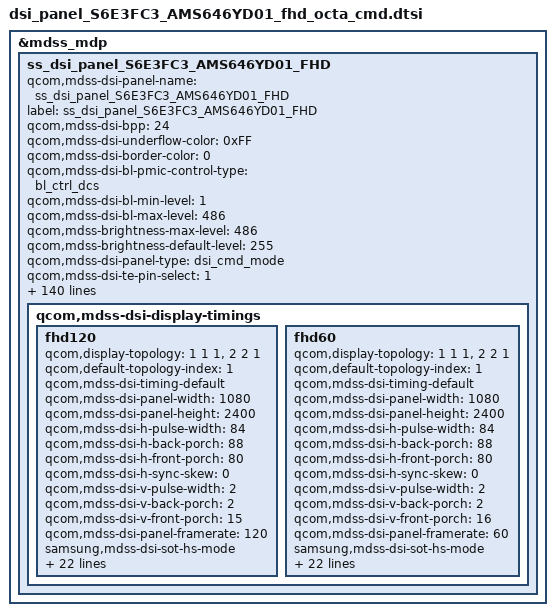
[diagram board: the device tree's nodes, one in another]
/* Copyright (c) 2012, Samsung Electronics Corporation. All rights reserved.
 *
 * This program is free software; you can redistribute it and/or modify
 * it under the terms of the GNU General Public License version 2 and
 * only version 2 as published by the Free Software Foundation.
 *
 * This program is distributed in the hope that it will be useful,
 * but WITHOUT ANY WARRANTY; without even the implied warranty of
 * MERCHANTABILITY or FITNESS FOR A PARTICULAR PURPOSE.  See the
 * GNU General Public License for more details.
 */

&mdss_mdp {
	ss_dsi_panel_S6E3FC3_AMS646YD01_FHD: ss_dsi_panel_S6E3FC3_AMS646YD01_FHD {
		qcom,mdss-dsi-panel-name = "ss_dsi_panel_S6E3FC3_AMS646YD01_FHD";
		label = "ss_dsi_panel_S6E3FC3_AMS646YD01_FHD";

		qcom,mdss-dsi-bpp = <24>;

		qcom,mdss-dsi-underflow-color = <0xFF>;
		qcom,mdss-dsi-border-color = <0>;

		qcom,mdss-dsi-bl-pmic-control-type = "bl_ctrl_dcs";

		qcom,mdss-dsi-bl-min-level = <1>;
		qcom,mdss-dsi-bl-max-level = <486>;
		qcom,mdss-brightness-max-level = <486>;
		qcom,mdss-brightness-default-level = <255>;

		qcom,mdss-dsi-panel-type = "dsi_cmd_mode";

		qcom,mdss-dsi-te-pin-select = <1>;

		qcom,mdss-dsi-te-dcs-command = <1>;
		qcom,mdss-dsi-wr-mem-start = <0x2C>;
		qcom,mdss-dsi-wr-mem-continue = <0x3C>;

		qcom,mdss-dsi-pixel-packing = "loose";

		qcom,mdss-dsi-virtual-channel-id = <0>;
		qcom,mdss-dsi-color-order = "rgb_swap_rgb";
		qcom,mdss-dsi-lane-0-state;
		qcom,mdss-dsi-lane-1-state;
		qcom,mdss-dsi-lane-2-state;
		qcom,mdss-dsi-lane-3-state;
		qcom,mdss-dsi-lane-map = "lane_map_0123";

		qcom,mdss-dsi-t-clk-pre = <0x3E>;
		qcom,mdss-dsi-t-clk-post = <0x10>;

		qcom,mdss-dsi-stream = <0>;
		qcom,mdss-dsi-mdp-trigger = "none";
		qcom,mdss-dsi-dma-trigger = "trigger_sw";

		qcom,mdss-pan-physical-width-dimension = <67>; /* 67.284 round-off */
		qcom,mdss-pan-physical-height-dimension = <150>; /* 149.520 round-off */

		qcom,mdss-dsi-reset-sequence = <0 10>, <1 10>;

		qcom,mdss-dsi-lp11-init;
		/*qcom,mdss-dsi-init-delay-us = <1000>;*/

		qcom,mdss-dsi-rx-eot-ignore;
		qcom,mdss-dsi-tx-eot-append;

		/* HDR Setting */
		/*qcom,mdss-dsi-panel-hdr-enabled;*/
		/*qcom,mdss-dsi-panel-hdr-color-primaries = <15635 16450 34000 16000 13250 34500 7500 3000>;*/
		/*qcom,mdss-dsi-panel-peak-brightness = <5400000>;*/
		/*qcom,mdss-dsi-panel-average-brightness = <2000000>;*/
		/*qcom,mdss-dsi-panel-blackness-level = <2000>;*/

		qcom,ulps-enabled;

		/* qcom,suspend-ulps-enabled; */
		qcom,esd-check-enabled;
		qcom,mdss-dsi-panel-status-check-mode ="irq_check";
		qcom,mdss-dsi-panel-status-irq-trigger1 = "falling";
		/*qcom,mdss-dsi-panel-status-read-length;*/
		/*qcom,mdss-dsi-panel-status-value;*/
		/*qcom,mdss-dsi-panel-status-irq-trigger1 = "rising";*/

		/* *************************************************************
		 * Below  parameters are samsung dependent thigs
		 * *************************************************************
		 */
		samsung,panel-vendor = "SDC";
		samsung,disp-model = "AMS646YD01";
		samsung,panel-lpm-enable;
		samsung,support_gamma_mode2;
		samsung,skip_read_on_pre;
		samsung,elvss_interpolation_temperature = <(-16)>;
		samsung,support_lpm;
		samsung,rsc_4_frame_idle;
		samsung,support_factory_panel_swap;
		samsung,support-optical-fingerprint;

		samsung,support_vrr_based_bl; /* VRR Variable Refresh Rate */

		//samsung,esd-irq-trigger1 = "falling"; /* FG_ERR */

		/* *************************************************************
		 *  SELF DISPLAY
		 * *************************************************************
		 */
		//ss,self_display = <&self_display_FC3_dtsi>;

		/* *************************************************************
		 *  Tx
		 * *************************************************************
		 */
		samsung,level0_key_enable_tx_cmds_revA	= [29 01 00 00 00 00 03 9F A5 A5]; /* PASSWD0 */
		samsung,level0_key_disable_tx_cmds_revA	= [29 01 00 00 00 00 03 9F 5A 5A]; /* PASSWD0 */
		samsung,level1_key_enable_tx_cmds_revA	= [29 01 00 00 00 00 03 F0 5A 5A]; /* PASSWD1 */
		samsung,level1_key_disable_tx_cmds_revA	= [29 01 00 00 00 00 03 F0 A5 A5]; /* PASSWD1 */
		samsung,level2_key_enable_tx_cmds_revA	= [29 01 00 00 00 00 03 FC 5A 5A];
		samsung,level2_key_disable_tx_cmds_revA	= [29 01 00 00 00 00 03 FC A5 A5];

		/* BRIGHTNESS_MAX_PACKET = 50 */
		samsung,brightness_tx_cmds_revA = [
			39 01 00 00 00 00 01 00
			39 01 00 00 00 00 01 00
			39 01 00 00 00 00 01 00
			39 01 00 00 00 00 01 00
			39 01 00 00 00 00 01 00
			39 01 00 00 00 00 01 00
			39 01 00 00 00 00 01 00
			39 01 00 00 00 00 01 00
			39 01 00 00 00 00 01 00
			39 01 00 00 00 00 01 00
			39 01 00 00 00 00 01 00
			39 01 00 00 00 00 01 00
			39 01 00 00 00 00 01 00
			39 01 00 00 00 00 01 00
			39 01 00 00 00 00 01 00
			39 01 00 00 00 00 01 00
			39 01 00 00 00 00 01 00
			39 01 00 00 00 00 01 00
			39 01 00 00 00 00 01 00
			39 01 00 00 00 00 01 00
			39 01 00 00 00 00 01 00
			39 01 00 00 00 00 01 00
			39 01 00 00 00 00 01 00
			39 01 00 00 00 00 01 00
			39 01 00 00 00 00 01 00
			39 01 00 00 00 00 01 00
			39 01 00 00 00 00 01 00
			39 01 00 00 00 00 01 00
			39 01 00 00 00 00 01 00
			39 01 00 00 00 00 01 00
			39 01 00 00 00 00 01 00
			39 01 00 00 00 00 01 00
			39 01 00 00 00 00 01 00
			39 01 00 00 00 00 01 00
			39 01 00 00 00 00 01 00
			39 01 00 00 00 00 01 00
			39 01 00 00 00 00 01 00
			39 01 00 00 00 00 01 00
			39 01 00 00 00 00 01 00
			39 01 00 00 00 00 01 00
			39 01 00 00 00 00 01 00
			39 01 00 00 00 00 01 00
			39 01 00 00 00 00 01 00
			39 01 00 00 00 00 01 00
			39 01 00 00 00 00 01 00
			39 01 00 00 00 00 01 00
			39 01 00 00 00 00 01 00
			39 01 00 00 00 00 01 00
			39 01 00 00 00 00 01 00
			39 01 00 00 00 00 01 00
		];

		samsung,display_on_tx_cmds_revA = [
			/* DSC PPS cmd unlock & lock LEVEL0 KEY */
			29 00 00 00 00 00 03 9F A5 A5
			05 00 00 00 00 00 02 29 00
			29 01 00 00 00 00 03 9F 5A 5A
		];

		samsung,display_off_tx_cmds_revA = [05 01 00 00 00 00 02 28 00];

		samsung,reg_read_pos_tx_cmds_revA = [29 00 00 00 00 00 04 B0 00 00 00];

		samsung,mtp_write_sysfs_tx_cmds_revA = [
			29 00 00 00 00 00 3D 00
			00 00 00 00 00 00 00 00 00 00
			00 00 00 00 00 00 00 00 00 00
			00 00 00 00 00 00 00 00 00 00
			00 00 00 00 00 00 00 00 00 00
			00 00 00 00 00 00 00 00 00 00
			00 00 00 00 00 00 00 00 00 00
		];

		samsung,smooth_dimming_off_tx_cmds_revA = [
			29 00 00 00 00 00 03 F0 5A 5A
			29 01 00 00 21 00 02 53 20
			29 01 00 00 00 00 03 F0 A5 A5
		];

		samsung,gamma_mode2_normal_tx_cmds_revI=[
			29 00 00 00 00 00 04 B0 00 91 63
			29 00 00 00 00 00 02 63 60	/* hbm setting 1 */

			29 00 00 00 00 00 04 B0 02 03 63
			29 00 00 00 00 00 03 63 f1 07	/* hbm setting 2 */

			29 00 00 00 00 00 02 53 20	/* dimming speed setting */
			29 00 00 00 00 00 03 51 03 FF	/* WRDISBV */
			29 00 00 00 00 00 02 B5 14	/* temperature */

			29 00 00 00 00 00 04 B0 02 03 63
			29 00 00 00 00 00 03 63 f0 00	/* hbm setting 2 */

			29 00 00 00 00 00 04 B0 00 76 63
			29 00 00 00 00 00 04 63 00 00 00 /* AOR */
		];

		samsung,gamma_mode2_normal_tx_cmds_revG=[
			29 00 00 00 00 00 03 91 02 01	 /* normal brightness */
			29 00 00 00 00 00 02 53 20	/* dimming speed setting */
			29 00 00 00 00 00 03 51 03 FF	/* WRDISBV */
			29 00 00 00 00 00 02 B5 14	/* temperature */
			29 00 00 00 00 00 04 B0 00 76 63
			29 00 00 00 00 00 04 63 00 00 00 /* AOR */
		];

		samsung,gamma_mode2_normal_tx_cmds_revA=[
			29 00 00 00 00 00 04 B0 00 91 63
			29 00 00 00 00 00 02 63 60	/* hbm setting 1 */

			29 00 00 00 00 00 04 B0 02 03 63
			29 00 00 00 00 00 03 63 f1 07	/* hbm setting 2 */

			29 00 00 00 00 00 02 53 20	/* dimming speed setting */
			29 00 00 00 00 00 03 51 03 FF	/* WRDISBV */
			29 00 00 00 00 00 02 B5 14	/* temperature */

			29 00 00 00 00 00 04 B0 02 03 63
			29 00 00 00 00 00 03 63 f0 00	/* hbm setting 2 */
		];

		samsung,gamma_mode2_hbm_tx_cmds_revI=[
			29 00 00 00 00 00 04 B0 00 91 63
			29 00 00 00 00 00 02 63 20	/* hbm setting 1 */

			29 00 00 00 00 00 04 B0 02 03 63
			29 00 00 00 00 00 03 63 f1 00	/* hbm setting 2 */

			29 00 00 00 00 00 02 53 E0	/* dimming speed setting */
			29 00 00 00 00 00 03 51 03 FF	/* WRDISBV */
			29 00 00 00 00 00 02 B5 14	/* temperature */

			29 00 00 00 00 00 04 B0 02 03 63
			29 00 00 00 00 00 03 63 f0 07	/* hbm setting 2 */

			29 00 00 00 00 00 04 B0 00 76 63
			29 00 00 00 00 00 04 63 00 00 00 /* AOR */
		];

		samsung,gamma_mode2_hbm_tx_cmds_revG=[
			29 00 00 00 00 00 03 91 02 00	 /* hbm brightness */
			29 00 00 00 00 00 02 53 E0	/* dimming speed setting */
			29 00 00 00 00 00 03 51 03 FF	/* WRDISBV */
			29 00 00 00 00 00 02 B5 14	/* temperature */
			29 00 00 00 00 00 04 B0 00 76 63
			29 00 00 00 00 00 04 63 00 00 00 /* AOR */
		];

		samsung,gamma_mode2_hbm_tx_cmds_revA=[
			29 00 00 00 00 00 04 B0 00 91 63
			29 00 00 00 00 00 02 63 20	/* hbm setting 1 */

			29 00 00 00 00 00 04 B0 02 03 63
			29 00 00 00 00 00 03 63 f1 00	/* hbm setting 2 */

			29 00 00 00 00 00 02 53 E0	/* dimming speed setting */
			29 00 00 00 00 00 03 51 03 FF	/* WRDISBV */
			29 00 00 00 00 00 02 B5 14	/* temperature */

			29 00 00 00 00 00 04 B0 02 03 63
			29 00 00 00 00 00 03 63 f0 07	/* hbm setting 2 */
		];

		samsung,vrr_tx_cmds_revA = [
			29 00 00 00 00 00 03 60 00 00
			29 00 00 00 00 00 02 F7 0F
		];

		samsung,acl_on_tx_cmds_revA = [
			29 00 00 00 00 00 04 B0 03 B3 65
			29 00 00 00 00 00 14 65
				55 00 B0 51 66 98 15 55 55 55	/* 32 Frame Avg & ACL start step 50% */
				08 F1 C6 48 40 00 20 10 09	/* ACL Dimming : 32 frame */
			29 00 00 00 00 00 02 55 03		/* normal ACL 15% & HBM ACL 8% */
		];

		samsung,acl_off_tx_cmds_revA = [
			29 01 00 00 00 00 02 55 00		/* ACL OFF */
		];

		/* *************************************************************
		 *  Rx (Module Information READ)
		 * *************************************************************
		 */
		samsung,manufacture_id0_rx_cmds_revA	= [06 01 00 00 00 00 01 da 01 00];
		samsung,manufacture_id1_rx_cmds_revA	= [06 01 00 00 00 00 01 db 01 00];
		samsung,manufacture_id2_rx_cmds_revA	= [06 01 00 00 00 00 01 dc 01 00];

		samsung,module_info_rx_cmds_revA = [06 01 00 00 00 00 01 A1 0B 00];
		samsung,octa_id_rx_cmds_revA	= [06 01 00 00 00 00 01 A1 04 0B]; /* OCTA ID : read A1 12th ~ 15th + Cell ID */
		samsung,cell_id_rx_cmds_revA	= [06 01 00 00 00 00 01 92 10 02]; /* CELL ID : read 92 3rd~18th bytes*/
		samsung,ddi_id_rx_cmds_revA	= [06 01 00 00 00 00 01 D6 05 00];

		samsung,mtp_read_sysfs_rx_cmds_revA = [06 01 00 00 00 00 01 00 00 00];

		/* *************************************************************
		 * candela to index mappings
		 * **************************************************************
		 */
		samsung,candela_map_table_revA = < /* THIS TABLE USED FOR DIMMING */
		/* <idx> <from> <till> <gm2_wrdisbv> <cd> */
			0	0	0	2	2
			1	1	1	2	2
			2	2	2	5	3
			3	3	3	5	3
			4	4	4	8	4
			5	5	5	8	4
			6	6	6	11	6
			7	7	7	11	6
			8	8	8	14	7
			9	9	9	14	7
			10	10	10	17	8
			11	11	11	20	9
			12	12	12	24	11
			13	13	13	24	11
			14	14	14	27	12
			15	15	15	29	13
			16	16	16	31	14
			17	17	17	34	15
			18	18	18	36	16
			19	19	19	39	17
			20	20	20	41	18
			21	21	21	44	19
			22	22	22	46	20
			23	23	23	49	21
			24	24	24	52	22
			25	25	25	54	23
			26	26	26	57	24
			27	27	27	60	25
			28	28	28	63	26
			29	29	29	66	27
			30	30	30	68	28
			31	31	31	71	29
			32	32	32	74	31
			33	33	33	77	32
			34	34	34	80	33
			35	35	35	83	34
			36	36	36	86	35
			37	37	37	89	37
			38	38	38	92	38
			39	39	39	95	39
			40	40	40	98	40
			41	41	41	102	42
			42	42	42	105	43
			43	43	43	108	44
			44	44	44	111	45
			45	45	45	114	47
			46	46	46	118	48
			47	47	47	121	49
			48	48	48	124	51
			49	49	49	128	52
			50	50	50	131	53
			51	51	51	134	55
			52	52	52	138	56
			53	53	53	141	57
			54	54	54	145	59
			55	55	55	148	60
			56	56	56	151	61
			57	57	57	155	63
			58	58	58	158	64
			59	59	59	162	65
			60	60	60	165	67
			61	61	61	169	68
			62	62	62	173	70
			63	63	63	176	71
			64	64	64	180	73
			65	65	65	183	74
			66	66	66	187	75
			67	67	67	191	77
			68	68	68	194	78
			69	69	69	198	80
			70	70	70	202	81
			71	71	71	205	83
			72	72	72	209	84
			73	73	73	213	86
			74	74	74	217	87
			75	75	75	220	89
			76	76	76	224	90
			77	77	77	228	92
			78	78	78	232	93
			79	79	79	236	95
			80	80	80	240	96
			81	81	81	243	98
			82	82	82	247	99
			83	83	83	251	101
			84	84	84	255	102
			85	85	85	259	104
			86	86	86	263	106
			87	87	87	267	107
			88	88	88	271	109
			89	89	89	275	110
			90	90	90	279	112
			91	91	91	283	113
			92	92	92	287	115
			93	93	93	291	117
			94	94	94	295	118
			95	95	95	299	120
			96	96	96	303	122
			97	97	97	307	123
			98	98	98	311	125
			99	99	99	315	126
			100	100	100	319	128
			101	101	101	324	130
			102	102	102	328	131
			103	103	103	332	133
			104	104	104	336	135
			105	105	105	340	136
			106	106	106	344	138
			107	107	107	349	140
			108	108	108	353	141
			109	109	109	357	143
			110	110	110	361	145
			111	111	111	366	146
			112	112	112	370	148
			113	113	113	374	150
			114	114	114	378	151
			115	115	115	383	153
			116	116	116	387	155
			117	117	117	391	157
			118	118	118	396	158
			119	119	119	400	160
			120	120	120	404	162
			121	121	121	409	163
			122	122	122	413	165
			123	123	123	418	167
			124	124	124	422	169
			125	125	125	426	170
			126	126	126	431	172
			127	127	127	435	174
			128	128	128	440	176
			129	129	129	444	177
			130	130	130	449	179
			131	131	131	453	181
			132	132	132	457	183
			133	133	133	462	185
			134	134	134	466	186
			135	135	135	470	188
			136	136	136	475	190
			137	137	137	479	192
			138	138	138	483	194
			139	139	139	487	195
			140	140	140	492	197
			141	141	141	496	199
			142	142	142	500	201
			143	143	143	505	203
			144	144	144	509	204
			145	145	145	513	206
			146	146	146	518	208
			147	147	147	522	210
			148	148	148	527	212
			149	149	149	531	214
			150	150	150	535	215
			151	151	151	540	217
			152	152	152	544	219
			153	153	153	549	221
			154	154	154	553	223
			155	155	155	558	225
			156	156	156	562	227
			157	157	157	566	229
			158	158	158	571	230
			159	159	159	575	232
			160	160	160	580	234
			161	161	161	584	236
			162	162	162	589	238
			163	163	163	593	240
			164	164	164	598	242
			165	165	165	603	244
			166	166	166	607	246
			167	167	167	612	247
			168	168	168	616	249
			169	169	169	621	251
			170	170	170	625	253
			171	171	171	630	255
			172	172	172	635	257
			173	173	173	639	259
			174	174	174	644	261
			175	175	175	648	263
			176	176	176	653	265
			177	177	177	658	267
			178	178	178	662	269
			179	179	179	667	271
			180	180	180	672	273
			181	181	181	676	275
			182	182	182	681	276
			183	183	183	686	278
			184	184	184	690	280
			185	185	185	695	282
			186	186	186	700	284
			187	187	187	704	286
			188	188	188	709	288
			189	189	189	714	290
			190	190	190	718	292
			191	191	191	723	294
			192	192	192	728	296
			193	193	193	733	298
			194	194	194	737	300
			195	195	195	742	302
			196	196	196	747	304
			197	197	197	752	306
			198	198	198	757	308
			199	199	199	761	310
			200	200	200	766	312
			201	201	201	771	314
			202	202	202	776	316
			203	203	203	781	318
			204	204	204	786	320
			205	205	205	790	322
			206	206	206	795	324
			207	207	207	800	326
			208	208	208	805	329
			209	209	209	810	331
			210	210	210	815	333
			211	211	211	820	335
			212	212	212	824	337
			213	213	213	829	339
			214	214	214	834	341
			215	215	215	839	343
			216	216	216	844	345
			217	217	217	847	346
			218	218	218	852	348
			219	219	219	856	350
			220	220	220	860	352
			221	221	221	864	354
			222	222	222	869	355
			223	223	223	873	357
			224	224	224	878	359
			225	225	225	882	361
			226	226	226	887	363
			227	227	227	892	365
			228	228	228	897	367
			229	229	229	903	370
			230	230	230	909	372
			231	231	231	913	374
			232	232	232	918	376
			233	233	233	923	378
			234	234	234	928	380
			235	235	235	932	382
			236	236	236	936	384
			237	237	237	940	385
			238	238	238	944	387
			239	239	239	949	389
			240	240	240	954	391
			241	241	241	959	393
			242	242	242	963	395
			243	243	243	968	397
			244	244	244	973	399
			245	245	245	978	401
			246	246	246	982	403
			247	247	247	988	405
			248	248	248	993	408
			249	249	249	999	410
			250	250	250	1004	412
			251	251	251	1008	414
			252	252	252	1012	415
			253	253	253	1015	417
			254	254	254	1019	418
			255	255	255	1023	420
		>;

		samsung,hbm_candela_map_table_revI = <
		/* <idx> <from> <till> <gm2_wrdisbv> <cd>*/
			0	256	256	2	427	0
			1	257	257	4	429	0
			2	258	258	6	430	0
			3	259	259	9	432	0
			4	260	260	12	434	0
			5	261	261	14	435	0
			6	262	262	17	437	0
			7	263	263	19	439	0
			8	264	264	21	440	0
			9	265	265	24	442	0
			10	266	266	27	443	0
			11	267	267	29	445	0
			12	268	268	32	446	0
			13	269	269	34	448	0
			14	270	270	36	450	0
			15	271	271	39	451	0
			16	272	272	42	453	0
			17	273	273	44	454	0
			18	274	274	47	456	0
			19	275	275	49	458	0
			20	276	276	51	459	0
			21	277	277	54	461	0
			22	278	278	57	463	0
			23	279	279	59	464	0
			24	280	280	62	466	0
			25	281	281	64	468	0
			26	282	282	66	469	0
			27	283	283	69	471	0
			28	284	284	72	473	0
			29	285	285	74	474	0
			30	286	286	77	476	0
			31	287	287	79	478	0
			32	288	288	81	479	0
			33	289	289	84	481	0
			34	290	290	87	482	0
			35	291	291	89	484	0
			36	292	292	92	485	0
			37	293	293	94	487	0
			38	294	294	96	488	0
			39	295	295	99	490	0
			40	296	296	102	492	0
			41	297	297	104	493	0
			42	298	298	106	495	0
			43	299	299	109	497	0
			44	300	300	111	498	0
			45	301	301	114	500	0
			46	302	302	117	502	0
			47	303	303	119	503	0
			48	304	304	121	505	0
			49	305	305	124	507	0
			50	306	306	126	508	0
			51	307	307	129	510	0
			52	308	308	132	512	0
			53	309	309	134	513	0
			54	310	310	136	515	0
			55	311	311	139	516	0
			56	312	312	141	518	0
			57	313	313	144	519	0
			58	314	314	147	521	0
			59	315	315	149	523	0
			60	316	316	151	524	0
			61	317	317	154	526	0
			62	318	318	156	527	0
			63	319	319	159	529	0
			64	320	320	162	531	0
			65	321	321	164	532	0
			66	322	322	166	534	0
			67	323	323	169	536	0
			68	324	324	171	537	0
			69	325	325	174	539	0
			70	326	326	177	541	0
			71	327	327	179	542	0
			72	328	328	181	544	0
			73	329	329	184	546	0
			74	330	330	186	547	0
			75	331	331	189	549	0
			76	332	332	192	551	0
			77	333	333	194	552	0
			78	334	334	196	554	0
			79	335	335	199	555	0
			80	336	336	201	557	0
			81	337	337	204	558	0
			82	338	338	207	560	0
			83	339	339	209	561	0
			84	340	340	211	563	0
			85	341	341	214	565	0
			86	342	342	216	566	0
			87	343	343	219	568	0
			88	344	344	222	570	0
			89	345	345	224	571	0
			90	346	346	226	573	0
			91	347	347	229	575	0
			92	348	348	231	576	0
			93	349	349	234	578	0
			94	350	350	237	580	0
			95	351	351	239	581	0
			96	352	352	241	583	0
			97	353	353	244	585	0
			98	354	354	246	586	0
			99	355	355	249	588	0
			100	356	356	252	589	0
			101	357	357	254	591	0
			102	358	358	256	593	0
			103	359	359	259	594	0
			104	360	360	261	596	0
			105	361	361	264	597	0
			106	362	362	267	599	0
			107	363	363	269	600	0
			108	364	364	271	602	0
			109	365	365	274	604	0
			110	366	366	276	605	0
			111	367	367	279	607	0
			112	368	368	281	608	0
			113	369	369	284	610	0
			114	370	370	286	612	0
			115	371	371	288	613	0
			116	372	372	291	615	0
			117	373	373	294	617	0
			118	374	374	296	618	0
			119	375	375	299	620	0
			120	376	376	301	622	0
			121	377	377	303	623	0
			122	378	378	306	625	0
			123	379	379	309	627	0
			124	380	380	311	628	0
			125	381	381	314	630	0
			126	382	382	316	631	0
			127	383	383	318	633	0
			128	384	384	321	634	0
			129	385	385	324	636	0
			130	386	386	326	638	0
			131	387	387	329	639	0
			132	388	388	331	641	0
			133	389	389	333	642	0
			134	390	390	336	644	0
			135	391	391	339	646	0
			136	392	392	341	647	0
			137	393	393	344	649	0
			138	394	394	346	651	0
			139	395	395	348	652	0
			140	396	396	351	654	0
			141	397	397	354	656	0
			142	398	398	356	657	0
			143	399	399	359	659	0
			144	400	400	361	661	0
			145	401	401	363	662	0
			146	402	402	366	664	0
			147	403	403	369	666	0
			148	404	404	371	667	0
			149	405	405	374	669	0
			150	406	406	376	670	0
			151	407	407	378	672	0
			152	408	408	381	673	0
			153	409	409	384	675	0
			154	410	410	386	676	0
			155	411	411	389	678	0
			156	412	412	391	680	0
			157	413	413	393	681	0
			158	414	414	396	683	0
			159	415	415	399	685	0
			160	416	416	401	686	0
			161	417	417	404	688	0
			162	418	418	406	690	0
			163	419	419	408	691	0
			164	420	420	411	693	0
			165	421	421	414	695	0
			166	422	422	416	696	0
			167	423	423	419	698	0
			168	424	424	421	700	0
			169	425	425	423	701	0
			170	426	426	426	703	0
			171	427	427	429	704	0
			172	428	428	431	706	0
			173	429	429	434	708	0
			174	430	430	436	709	0
			175	431	431	438	711	0
			176	432	432	441	712	0
			177	433	433	444	714	0
			178	434	434	446	715	0
			179	435	435	449	717	0
			180	436	436	451	719	0
			181	437	437	453	720	0
			182	438	438	456	722	0
			183	439	439	459	724	0
			184	440	440	461	725	0
			185	441	441	464	727	0
			186	442	442	466	729	0
			187	443	443	468	730	0
			188	444	444	471	732	0
			189	445	445	474	734	0
			190	446	446	476	735	0
			191	447	447	479	737	0
			192	448	448	481	739	0
			193	449	449	483	740	0
			194	450	450	486	742	0
			195	451	451	489	743	0
			196	452	452	491	745	0
			197	453	453	494	746	0
			198	454	454	496	748	0
			199	455	455	498	749	0
			200	456	456	501	751	0
			201	457	457	504	753	0
			202	458	458	506	754	0
			203	459	459	509	756	0
			204	460	460	511	758	0
			205	461	461	513	759	0
			206	462	462	516	761	0
			207	463	463	519	763	0
			208	464	464	521	764	0
			209	465	465	524	766	0
			210	466	466	526	768	0
			211	467	467	528	769	0
			212	468	468	531	771	0
			213	469	469	534	773	0
			214	470	470	536	774	0
			215	471	471	539	776	0
			216	472	472	541	777	0
			217	473	473	543	779	0
			218	474	474	546	781	0
			219	475	475	549	782	0
			220	476	476	551	784	0
			221	477	477	554	785	0
			222	478	478	556	787	0
			223	479	479	558	788	0
			224	480	480	561	790	0
			225	481	481	564	792	0
			226	482	482	566	793	0
			227	483	483	569	795	0
			228	484	484	571	797	0
			229	485	485	573	798	0
			230	486	486	576	800	0
		>;

		samsung,hbm_candela_map_table_revA = <
		/* <idx> <from> <till> <gm2_wrdisbv> <cd>*/
			0	256	256	2	427	0
			1	257	257	4	429	0
			2	258	258	6	430	0
			3	259	259	9	432	0
			4	260	260	12	434	0
			5	261	261	14	435	0
			6	262	262	17	437	0
			7	263	263	19	439	0
			8	264	264	21	440	0
			9	265	265	24	442	0
			10	266	266	27	443	0
			11	267	267	29	445	0
			12	268	268	32	446	0
			13	269	269	34	448	0
			14	270	270	36	450	0
			15	271	271	39	451	0
			16	272	272	42	453	0
			17	273	273	44	454	0
			18	274	274	47	456	0
			19	275	275	49	458	0
			20	276	276	51	459	0
			21	277	277	54	461	0
			22	278	278	57	463	0
			23	279	279	59	464	0
			24	280	280	62	466	0
			25	281	281	64	468	0
			26	282	282	66	469	0
			27	283	283	69	471	0
			28	284	284	72	473	0
			29	285	285	74	474	0
			30	286	286	77	476	0
			31	287	287	79	478	0
			32	288	288	81	479	0
			33	289	289	84	481	0
			34	290	290	87	482	0
			35	291	291	89	484	0
			36	292	292	92	485	0
			37	293	293	94	487	0
			38	294	294	96	488	0
			39	295	295	99	490	0
			40	296	296	102	492	0
			41	297	297	104	493	0
			42	298	298	106	495	0
			43	299	299	109	497	0
			44	300	300	111	498	0
			45	301	301	114	500	0
			46	302	302	117	502	0
			47	303	303	119	503	0
			48	304	304	121	505	0
			49	305	305	124	507	0
			50	306	306	126	508	0
			51	307	307	129	510	0
			52	308	308	132	512	0
			53	309	309	134	513	0
			54	310	310	136	515	0
			55	311	311	139	516	0
			56	312	312	141	518	0
			57	313	313	144	519	0
			58	314	314	147	521	0
			59	315	315	149	523	0
			60	316	316	151	524	0
			61	317	317	154	526	0
			62	318	318	156	527	0
			63	319	319	159	529	0
			64	320	320	162	531	0
			65	321	321	164	532	0
			66	322	322	166	534	0
			67	323	323	169	536	0
			68	324	324	171	537	0
			69	325	325	174	539	0
			70	326	326	177	541	0
			71	327	327	179	542	0
			72	328	328	181	544	0
			73	329	329	184	546	0
			74	330	330	186	547	0
			75	331	331	189	549	0
			76	332	332	192	551	0
			77	333	333	194	552	0
			78	334	334	196	554	0
			79	335	335	199	555	0
			80	336	336	201	557	0
			81	337	337	204	558	0
			82	338	338	207	560	0
			83	339	339	209	561	0
			84	340	340	211	563	0
			85	341	341	214	565	0
			86	342	342	216	566	0
			87	343	343	219	568	0
			88	344	344	222	570	0
			89	345	345	224	571	0
			90	346	346	226	573	0
			91	347	347	229	575	0
			92	348	348	231	576	0
			93	349	349	234	578	0
			94	350	350	237	580	0
			95	351	351	239	581	0
			96	352	352	241	583	0
			97	353	353	244	585	0
			98	354	354	246	586	0
			99	355	355	249	588	0
			100	356	356	252	589	0
			101	357	357	254	591	0
			102	358	358	256	593	0
			103	359	359	259	594	0
			104	360	360	261	596	0
			105	361	361	264	597	0
			106	362	362	267	599	0
			107	363	363	269	600	0
			108	364	364	271	602	0
			109	365	365	274	604	0
			110	366	366	276	605	0
			111	367	367	279	607	0
			112	368	368	281	608	0
			113	369	369	284	610	0
			114	370	370	286	612	0
			115	371	371	288	613	0
			116	372	372	291	615	0
			117	373	373	294	617	0
			118	374	374	296	618	0
			119	375	375	299	620	0
			120	376	376	301	622	0
			121	377	377	303	623	0
			122	378	378	306	625	0
			123	379	379	309	627	0
			124	380	380	311	628	0
			125	381	381	314	630	0
			126	382	382	316	631	0
			127	383	383	318	633	0
			128	384	384	321	634	0
			129	385	385	324	636	0
			130	386	386	326	638	0
			131	387	387	329	639	0
			132	388	388	331	641	0
			133	389	389	333	642	0
			134	390	390	336	644	0
			135	391	391	339	646	0
			136	392	392	341	647	0
			137	393	393	344	649	0
			138	394	394	346	651	0
			139	395	395	348	652	0
			140	396	396	351	654	0
			141	397	397	354	656	0
			142	398	398	356	657	0
			143	399	399	359	659	0
			144	400	400	361	661	0
			145	401	401	363	662	0
			146	402	402	366	664	0
			147	403	403	369	666	0
			148	404	404	371	667	0
			149	405	405	374	669	0
			150	406	406	376	670	0
			151	407	407	378	672	0
			152	408	408	381	673	0
			153	409	409	384	675	0
			154	410	410	386	676	0
			155	411	411	389	678	0
			156	412	412	391	680	0
			157	413	413	393	681	0
			158	414	414	396	683	0
			159	415	415	399	685	0
			160	416	416	401	686	0
			161	417	417	404	688	0
			162	418	418	406	690	0
			163	419	419	408	691	0
			164	420	420	411	693	0
			165	421	421	414	695	0
			166	422	422	416	696	0
			167	423	423	419	698	0
			168	424	424	421	700	0
			169	425	425	423	701	0
			170	426	426	426	703	0
			171	427	427	429	704	0
			172	428	428	431	706	0
			173	429	429	434	708	0
			174	430	430	436	709	0
			175	431	431	438	711	0
			176	432	432	441	712	0
			177	433	433	444	714	0
			178	434	434	446	715	0
			179	435	435	449	717	0
			180	436	436	451	719	0
			181	437	437	453	720	0
			182	438	438	456	722	0
			183	439	439	459	724	0
			184	440	440	461	725	0
			185	441	441	464	727	0
			186	442	442	466	729	0
			187	443	443	468	730	0
			188	444	444	471	732	0
			189	445	445	474	734	0
			190	446	446	476	735	0
			191	447	447	479	737	0
			192	448	448	481	739	0
			193	449	449	483	740	0
			194	450	450	486	742	0
			195	451	451	489	743	0
			196	452	452	491	745	0
			197	453	453	494	746	0
			198	454	454	496	748	0
			199	455	455	498	749	0
			200	456	456	501	751	0
			201	457	457	504	753	0
			202	458	458	506	754	0
			203	459	459	509	756	0
			204	460	460	511	758	0
			205	461	461	513	759	0
			206	462	462	516	761	0
			207	463	463	519	763	0
			208	464	464	521	764	0
			209	465	465	524	766	0
			210	466	466	526	768	0
			211	467	467	528	769	0
			212	468	468	531	771	0
			213	469	469	534	773	0
			214	470	470	536	774	0
			215	471	471	539	776	0
			216	472	472	541	777	0
			217	473	473	543	779	0
			218	474	474	546	781	0
			219	475	475	549	782	0
			220	476	476	551	784	0
			221	477	477	554	785	0
			222	478	478	556	787	0
			223	479	479	558	788	0
			224	480	480	561	790	0
			225	481	481	564	792	0
			226	482	482	566	793	0
			227	483	483	569	795	0
			228	484	484	571	797	0
			229	485	485	573	798	0
			230	486	486	576	800	0
		>;

		samsung,aod_candela_map_table_revA = <
		/*   <idx>   <from>  <till>  <gm2_wrdisbv> <cd> */
			0	0	12	27	2
			1	13	31	26	10
			2	32	54	25	30
			3	55	255	24	60
		>;

		/* *************************************************************
		 * Dynamic MIPI Clock
		 * **************************************************************
		 */
		samsung,support_dynamic_mipi_clk;

		samsung,ffc_tx_cmds_revA = [
			29 00 00 00 00 00 03 F0 5A 5A
			29 00 00 00 00 00 03 FC 5A 5A

			/* 0. Default 1110 Mbps */
			29 00 00 00 00 00 04 B0 00 2A C5
			29 00 00 00 00 00 05 C5 0D 10 80 45
			29 00 00 00 00 00 04 B0 00 2E C5
			29 00 00 00 00 00 03 C5 53 A0

			29 00 00 00 00 00 02 F7 0F
			29 00 00 00 00 00 03 FC A5 A5
			29 00 00 00 00 00 03 F0 A5 A5
		];

		samsung,dyn_mipi_clk_ffc_cmds_revA = [
			/* 0. Default 1110 Mbps */
			29 00 00 00 00 00 04 B0 00 2A C5
			29 00 00 00 00 00 05 C5 0D 10 80 45
			29 00 00 00 00 00 04 B0 00 2E C5
			29 00 00 00 00 00 03 C5 53 A0

			/* 1. Default 1114 Mbps */
			29 00 00 00 00 00 04 B0 00 2A C5
			29 00 00 00 00 00 05 C5 0D 10 80 45
			29 00 00 00 00 00 04 B0 00 2E C5
			29 00 00 00 00 00 03 C5 53 54

			/* 2. Default 1124 Mbps */
			29 00 00 00 00 00 04 B0 00 2A C5
			29 00 00 00 00 00 05 C5 0D 10 80 45
			29 00 00 00 00 00 04 B0 00 2E C5
			29 00 00 00 00 00 03 C5 52 96
		];

		samsung,dynamic_mipi_clk_timing_table = <
			/*<bitclk><>*/
			1110000000 /* clk id 0 default */
			1114000000 /* clk id 1 */
			1124000000 /* clk id 2 */
		>;

		samsung,dynamic_mipi_clk_sel_table = <
			/*<RAT><BAND><from><end><clk index>*/
			1		1		0		0		0
			1		2		0		0		0
			1		3		0		0		2
			1		4		0		0		1
			2		11		10562		10838		0
			2		12		9662		9677		0
			2		12		9678		9712		1
			2		12		9713		9747		2
			2		12		9748		9938		0
			2		13		1162		1178		2
			2		13		1179		1513		0
			2		14		1537		1738		0
			2		15		4357		4458		0
			2		17		2237		2271		0
			2		17		2272		2318		1
			2		17		2319		2341		2
			2		17		2342		2563		0
			2		18		2937		3088		0
			3		91		0		599		0
			3		92		600		654		0
			3		92		655		724		1
			3		92		725		794		2
			3		92		795		1199		0
			3		93		1200		1257		2
			3		93		1258		1949		0
			3		94		1950		2399		0
			3		95		2400		2649		0
			3		97		2750		2842		0
			3		97		2843		2937		1
			3		97		2938		2982		2
			3		97		2983		3449		0
			3		98		3450		3799		0
			3		102		5010		5179		0
			3		103		5180		5279		0
			3		104		5280		5379		0
			3		107		5730		5849		0
			3		108		5850		5999		0
			3		109		6000		6149		0
			3		110		6150		6449		0
			3		111		6450		6599		0
			3		115		8040		8094		0
			3		115		8095		8164		1
			3		115		8165		8234		2
			3		115		8235		8689		0
			3		116		8690		9039		0
			3		118		9210		9659		0
			3		119		9660		9769		0
			3		120		9770		9787		0
			3		120		9788		9869		1
			3		122		9920		10359		0
			3		124		36200		36349		0
			3		128		37750		38249		0
			3		129		38250		38649		0
			3		130		38650		39167		0
			3		130		39168		39252		1
			3		130		39253		39307		2
			3		130		39308		39649		0
			3		131		39650		39684		1
			3		131		39685		39734		2
			3		131		39735		40982		0
			3		131		40983		41077		1
			3		131		41078		41122		2
			3		131		41123		41589		0
			3		132		41590		42207		0
			3		132		42208		42332		1
			3		132		42333		42347		2
			3		132		42348		43589		0
			3		138		55240		55745		0
			3		138		55746		55875		1
			3		138		55876		55885		2
			3		138		55886		56739		0
			3		156		66436		67335		0
			3		161		68586		68935		0
			4		51		0		0		0
			4		52		0		0		0
			4		53		0		0		0
			4		54		0		0		0
			4		55		0		0		2
			4		56		0		0		0
			5		61		0		0		0
			5		62		0		0		0
			5		71		0		0		0
			7		260		173800		178780		0
			7		263		185000		191840		0
			7		263		191841		191980		1
			7		283		151600		160580		0
			7		326		123400		130380		0
		>;

		/*
		 * ************************************************************************************************************************
		 *  FD Settings
		 * ************************************************************************************************************************
		 */

		samsung,fd_on_tx_cmds_revA = [
			/* Display PMIC FD On */
			29 00 00 00 00 00 03 F0 5A 5A	/* TEST KEY Enable */
			29 00 00 00 00 00 04 B0 00 0A B5
			29 00 00 00 00 00 03 B5 40 40		/* Setting */
			29 01 00 00 00 00 03 F0 A5 A5	/* TEST KEY Disable */
		];

		samsung,fd_off_tx_cmds_revA = [
			/* Display PMIC FD Off */
			29 00 00 00 00 00 03 F0 5A 5A	/* TEST KEY Enable */
			29 00 00 00 00 00 04 B0 00 0A B5
			29 00 00 00 00 00 03 B5 80 40		/* Setting */
			29 01 00 00 00 00 03 F0 A5 A5	/* TEST KEY Disable */
		];

		/* *************************************************************
		 *   APLPM
		 * *************************************************************
		 */
		samsung,self_grid_on_revA = [
			/* TIG Enable */
			29 00 00 00 00 00 03 F0 5A 5A
			29 00 00 00 00 00 03 BF 01 00
			29 01 00 00 11 00 03 F0 A5 A5	/* wait 16.7ms */
		];

		samsung,self_grid_off_revA = [
			/* TIG Disable */
			29 01 00 00 11 00 03 F0 5A 5A	/* wait 16.7ms */
			29 00 00 00 00 00 03 BF 00 00
			29 01 00 00 00 00 03 F0 A5 A5
		];

		samsung,lpm_on_tx_cmds_revI = [
			29 00 00 00 00 00 03 F0 5A 5A
			29 00 00 00 00 00 03 91 01 01 /* AOD Setting */
			29 00 00 00 00 00 02 53 27
			29 00 00 00 00 00 04 B0 01 88 CB
			29 00 00 00 00 00 08 CB 40 0A 00 00 00 00 40 /* HFP Setting */
			29 00 00 00 00 00 04 B0 01 C0 CB
			29 00 00 00 00 00 08 CB 38 00 00 00 18 03 38 /* HFP Setting */
			29 00 00 00 00 00 04 B0 00 10 F2
			29 00 00 00 00 00 03 F2 24 A4	/* HFP Setting */
			29 01 00 00 00 00 02 F7 0F 	/* 10ns dealy */
			29 01 00 00 11 00 03 F0 A5 A5 /* wait 16.7ms */
		];

		samsung,lpm_on_tx_cmds_revA = [
			29 00 00 00 00 00 03 F0 5A 5A
			29 00 00 00 00 00 03 91 01 01	/* AOD Setting */
			29 00 00 00 00 00 02 53 27
			29 00 00 00 00 00 04 B0 01 88 CB
			29 00 00 00 00 00 08 CB 40 0A 00 00 00 00 40	/* HFP Setting */
			29 00 00 00 00 00 04 B0 01 C0 CB
			29 00 00 00 00 00 08 CB 38 00 00 00 18 03 38	/* HFP Setting */
			29 00 00 00 00 00 04 B0 00 10 F2
			29 00 00 00 00 00 03 F2 24 A4	/* HFP Setting */
			29 01 00 00 00 00 02 F7 0F	/* 10ns dealy */
			29 01 00 00 00 00 03 F0 A5 A5	/* 16.7ms Delay is moved to self_grid_on cmd */
		];

		samsung,lpm_off_tx_cmds_revI = [
			29 00 00 00 00 00 03 F0 5A 5A
			29 00 00 00 00 00 04 B0 00 07 B5
			29 00 00 00 00 00 04 B5 00 00 00  /* A SWIRE No Pulse */
			29 00 00 00 00 00 04 B0 01 88 CB
			29 00 00 00 00 00 08 CB 45 0A 00 00 00 00 45 /* HFP Setting*/
			29 00 00 00 00 00 04 B0 01 C0 CB
			29 00 00 00 00 00 08 CB 3D 00 00 00 18 03 3D /* HFP Setting*/
			29 00 00 00 00 00 04 B0 00 10 F2
			29 00 00 00 00 00 03 F2 26 F0 /* HFP Setting*/
			29 00 00 00 00 00 03 91 02 01 /* Normal Setting */
			29 00 00 00 00 00 02 53 20 /* Normal Mode*/
			29 00 00 00 00 00 02 F7 0F
			29 01 00 00 00 00 03 F0 A5 A5 /* wait 33.4ms at lpm code*/
		];

		samsung,lpm_off_tx_cmds_revA = [
			29 00 00 00 00 00 03 F0 5A 5A
			29 00 00 00 00 00 04 B0 00 07 B5
			29 00 00 00 00 00 04 B5 00 00 00  /* A SWIRE No Pulse */
			29 00 00 00 00 00 04 B0 01 88 CB
			29 00 00 00 00 00 08 CB 45 0A 00 00 00 00 45	/* HFP Setting*/
			29 00 00 00 00 00 04 B0 01 C0 CB
			29 00 00 00 00 00 08 CB 3D 00 00 00 18 03 3D	/* HFP Setting*/
			29 00 00 00 00 00 04 B0 00 10 F2
			29 00 00 00 00 00 03 F2 26 E4		/* HFP Setting*/
			29 00 00 00 00 00 03 91 02 01		/* Normal Setting */
			29 00 00 00 00 00 04 B0 00 91 63
			29 00 00 00 00 00 02 63 20
			29 00 00 00 00 00 02 53 20		/* Normal Mode*/
			29 00 00 00 00 00 02 F7 0F
			29 01 00 00 00 00 03 F0 A5 A5		/* wait 33.4ms at lpm code*/
		];

		/* ALPM/HLPM 60/30/10/2nit control */
		samsung,lpm_60nit_tx_cmds_revA = [29 00 00 00 00 00 02 53 24];
		samsung,lpm_30nit_tx_cmds_revA = [29 00 00 00 00 00 02 53 25];
		samsung,lpm_10nit_tx_cmds_revA = [29 00 00 00 00 00 02 53 26];
		samsung,lpm_2nit_tx_cmds_revA = [29 00 00 00 00 00 02 53 27];

		/* HLPM / ALPM brightness Commands: default alpm 2nit */
		samsung,lpm_brightnes_tx_cmds_revA		= [
			29 00 00 00 00 00 03 F0 5A 5A
			29 00 00 00 00 00 02 53 26
			29 00 00 00 00 00 02 F7 0F
			29 01 00 00 00 00 03 F0 A5 A5
		];

		/*
		* ************************************************************************************************************************
		*  DMS (Dynamic Mode Switch)
		* ************************************************************************************************************************
		*/

		qcom,mdss-dsi-display-timings {
			fhd120 {
				qcom,display-topology = <1 1 1>, <2 2 1>; // lm, enc, intf // JUN_TEMP_R8
				qcom,default-topology-index = <1>;  // JUN_TEMP_R8 : 0 => 1
				qcom,mdss-dsi-timing-default;
				qcom,mdss-dsi-panel-width = <1080>;
				qcom,mdss-dsi-panel-height = <2400>;

				qcom,mdss-dsi-h-pulse-width = <84>;
				qcom,mdss-dsi-h-back-porch = <88>;
				qcom,mdss-dsi-h-front-porch = <80>;
				qcom,mdss-dsi-h-sync-skew = <0>;

				qcom,mdss-dsi-v-pulse-width = <2>;
				qcom,mdss-dsi-v-back-porch = <2>;
				qcom,mdss-dsi-v-front-porch = <15>;

				qcom,mdss-dsi-panel-framerate = <120>;
				samsung,mdss-dsi-sot-hs-mode;

				/* transfer time: 48Hz: 20032, 60Hz: 15866, 96Hz: 9616, 120Hz: 7533 */
				qcom,mdss-mdp-transfer-time-us = <7533>;
				qcom,mdss-dsi-panel-clockrate = <1108000000>; /* ((1080 * 2400 * 24 * 132.7492367) / 4 ) / 3 ~ 1.9G*/
				//qcom,mdss-dsi-panel-phy-timings =[00 25 0A 0A 27 24 0A 0A 0A 02 04 00];
				qcom,mdss-dsi-panel-phy-timings = [00 25 0A 0A 27 24 0A 0A 09 02 04 00 20 0F];

				qcom,mdss-dsi-t-clk-pre = <0x20>;
				qcom,mdss-dsi-t-clk-post = <0x0F>;

				qcom,mdss-dsi-on-command = [
					/* Sleep out, wait 30ms (0x1E) */
					05 01 00 00 1E 00 02 11 00

					29 00 00 00 00 00 03 F0 5A 5A

					/* Global Para Setting */
					29 00 00 00 00 00 2A F2
						00 05 0E 58 54 01 0C 00
						04 27 24 2F B0 0C 09 74
						26 E4 0C 00 04 10 00 10
						26 A8 10 00 10 10 34 10
						00 40 30 C8 00 C8 00 00
						CE

					/* TE Vsync On */
					29 00 00 00 00 00 02 35 00

					/* PAGE Address Setting */
					29 00 00 00 00 00 05 2A 00 00 04 37
					29 00 00 00 00 00 05 2B 00 00 09 5F

					/* FFC Setting */

					/* ERR_FG Setting */
					29 00 00 00 00 00 02 E5 15
					29 00 00 00 00 00 04 ED 44 4C 20

					/* Vsync Setting */
					29 00 00 00 00 00 04 B0 00 04 F2
					29 00 00 00 00 00 02 F2 54

					/* PCD  Setting */
					29 00 00 00 00 00 03 CC 5C 51

					/* DSC setting */
					07 01 00 00 00 00 01 01		/* DSC enable :  Compression Mode*/
					0A 01 00 00 00 00 80		/* PPS setting */
						11 00 00 89 30 80 09 60
						04 38 00 28 02 1C 02 1C
						02 00 02 0E 00 20 03 DD
						00 07 00 0C 02 77 02 8B
						18 00 10 F0 03 0C 20 00
						06 0B 0B 33 0E 1C 2A 38
						46 54 62 69 70 77 79 7B
						7D 7E 01 02 01 00 09 40
						09 BE 19 FC 19 FA 19 F8
						1A 38 1A 78 1A B6 2A F6
						2B 34 2B 74 3B 74 6B F4
						00 00 00 00 00 00 00 00
						00 00 00 00 00 00 00 00
						00 00 00 00 00 00 00 00
						00 00 00 00 00 00 00 00
						00 00 00 00 00 00 00 00

					/* Freq setting */
					29 00 00 00 00 00 04 B0 00 27 F2
					29 00 00 00 00 00 02 F2 00

					/* Porch Clock Set */
					29 00 00 00 00 00 04 B0 00 2E F2
					29 00 00 00 00 00 02 F2 55

					29 00 00 00 00 00 04 B0 00 92 63
					29 00 00 00 00 00 02 63 04	/* smooth dimming 4frame*/

					29 00 00 00 00 00 02 F7 0F
					29 01 00 00 5A 00 03 F0 A5 A5	/* wait 90ms (0x5A) */
				];

				qcom,mdss-dsi-off-command = [
					/* DSC PPS cmd unlock & lock LEVEL0 KEY */
					29 00 00 00 00 00 03 9F A5 A5
					05 01 00 00 14 00 02 28 00 /* wait 20ms */
					05 01 00 00 78 00 02 10 00 /* wait 120ms */
					29 01 00 00 00 00 03 9F 5A 5A
				];

				qcom,mdss-dsi-on-command-state = "dsi_hs_mode";
				qcom,mdss-dsi-off-command-state = "dsi_hs_mode";

				//qcom,partial-update-enabled = "single_roi";
				// JUN_TEMP_R8 qcom,panel-roi-alignment=<1080 40 1080 40 1080 40>;

				qcom,compression-mode = "dsc";
				qcom,lm-split = <540 540>;
				qcom,mdss-dsc-encoders = <2>;
				qcom,mdss-dsc-slice-height = <40>;
				qcom,mdss-dsc-slice-width = <540>;
				qcom,mdss-dsc-slice-per-pkt = <1>;
				qcom,mdss-dsc-bit-per-component = <8>;
				qcom,mdss-pps-delay-ms = <0>;
				qcom,mdss-dsc-bit-per-pixel = <8>;
				qcom,mdss-dsc-block-prediction-enable;
			};

			fhd60 {
				qcom,display-topology = <1 1 1>, <2 2 1>; // JUN_TEMP_R8
				qcom,default-topology-index = <1>;  // JUN_TEMP_R8 : 0 => 1
				qcom,mdss-dsi-timing-default;
				qcom,mdss-dsi-panel-width = <1080>;
				qcom,mdss-dsi-panel-height = <2400>;

				qcom,mdss-dsi-h-pulse-width = <84>;
				qcom,mdss-dsi-h-back-porch = <88>;
				qcom,mdss-dsi-h-front-porch = <80>;
				qcom,mdss-dsi-h-sync-skew = <0>;

				qcom,mdss-dsi-v-pulse-width = <2>;
				qcom,mdss-dsi-v-back-porch = <2>;
				qcom,mdss-dsi-v-front-porch = <16>;

				qcom,mdss-dsi-panel-framerate = <60>;
				samsung,mdss-dsi-sot-hs-mode;

				/* transfer time: 48Hz: 20032, 60Hz: 15866, 96Hz: 9616, 120Hz: 7533 */
				qcom,mdss-mdp-transfer-time-us = <15866>;
				qcom,mdss-dsi-panel-clockrate = <1108000000>; /* ((1080 * 2400 * 24 * 132.7492367) / 4 ) / 3 ~ 1.9G*/
				//qcom,mdss-dsi-panel-phy-timings =[00 25 0A 0A 27 24 0A 0A 0A 02 04 00];
				qcom,mdss-dsi-panel-phy-timings = [00 25 0A 0A 27 24 0A 0A 09 02 04 00 20 0F];
				qcom,mdss-dsi-t-clk-pre = <0x20>;
				qcom,mdss-dsi-t-clk-post = <0x0F>;

				qcom,mdss-dsi-on-command = [
					/* Sleep out, wait 30ms (0x1E) */
					05 01 00 00 1E 00 02 11 00

					29 00 00 00 00 00 03 F0 5A 5A

					/* Global Para Setting */
					29 00 00 00 00 00 2A F2
						00 05 0E 58 54 01 0C 00
						04 27 24 2F B0 0C 09 74
						26 E4 0C 00 04 10 00 10
						26 A8 10 00 10 10 3C 10
						00 40 30 C8 00 C8 00 00
						CE

					/* TE Vsync On */
					29 00 00 00 00 00 02 35 00

					/* PAGE Address Setting */
					29 00 00 00 00 00 05 2A 00 00 04 37
					29 00 00 00 00 00 05 2B 00 00 09 5F

					/* FFC Setting */

					/* ERR_FG Setting */
					29 00 00 00 00 00 02 E5 15
					29 00 00 00 00 00 04 ED 44 4C 20

					/* Vsync Setting */
					29 00 00 00 00 00 04 B0 00 04 F2
					29 00 00 00 00 00 02 F2 54

					/* PCD  Setting */
					29 00 00 00 00 00 03 CC 5C 51

					/* DSC setting */
					07 01 00 00 00 00 01 01		/* DSC enable :  Compression Mode*/
					0A 01 00 00 00 00 80		/* PPS setting */
						11 00 00 89 30 80 09 60
						04 38 00 28 02 1C 02 1C
						02 00 02 0E 00 20 03 DD
						00 07 00 0C 02 77 02 8B
						18 00 10 F0 03 0C 20 00
						06 0B 0B 33 0E 1C 2A 38
						46 54 62 69 70 77 79 7B
						7D 7E 01 02 01 00 09 40
						09 BE 19 FC 19 FA 19 F8
						1A 38 1A 78 1A B6 2A F6
						2B 34 2B 74 3B 74 6B F4
						00 00 00 00 00 00 00 00
						00 00 00 00 00 00 00 00
						00 00 00 00 00 00 00 00
						00 00 00 00 00 00 00 00
						00 00 00 00 00 00 00 00

					/* Freq setting */
					29 00 00 00 00 00 04 B0 00 27 F2
					29 00 00 00 00 00 02 F2 00

					/* Porch Clock Set */
					29 00 00 00 00 00 04 B0 00 2E F2
					29 00 00 00 00 00 02 F2 55

					29 00 00 00 00 00 04 B0 00 92 63
					29 00 00 00 00 00 02 63 04	/* smooth dimming 4frame*/

					29 00 00 00 00 00 02 F7 0F
					29 01 00 00 5A 00 03 F0 A5 A5	/* wait 90ms (0x5A) */
				];

				qcom,mdss-dsi-off-command = [
					/* DSC PPS cmd unlock & lock LEVEL0 KEY */
					29 00 00 00 00 00 03 9F A5 A5
					05 01 00 00 14 00 02 28 00 /* wait 20ms */
					05 01 00 00 78 00 02 10 00 /* wait 120ms */
					29 01 00 00 00 00 03 9F 5A 5A
				];

				qcom,mdss-dsi-on-command-state = "dsi_hs_mode";
				qcom,mdss-dsi-off-command-state = "dsi_hs_mode";

				//qcom,partial-update-enabled = "single_roi";
				// JUN_TEMP_R8 qcom,panel-roi-alignment=<1080 40 1080 40 1080 40>;

				qcom,compression-mode = "dsc";
				qcom,lm-split = <540 540>;
				qcom,mdss-dsc-encoders = <2>;
				qcom,mdss-dsc-slice-height = <40>;
				qcom,mdss-dsc-slice-width = <540>;
				qcom,mdss-dsc-slice-per-pkt = <1>;
				qcom,mdss-dsc-bit-per-component = <8>;
				qcom,mdss-pps-delay-ms = <0>;
				qcom,mdss-dsc-bit-per-pixel = <8>;
				qcom,mdss-dsc-block-prediction-enable;
			};
		};
	};
};
